# STM32C091 register map
File version: 1.1
CPU: CM0+ r0p0, little endian, MPU, no FPU, 4 interrupt priority bits
Registers are 32-bit, read-write, reset 0x0 unless marked. A register's access mark holds for its fields unless they carry their own. Offsets are from the block's base; [hi:lo] are bit positions; {n}, {i} and the like mark numbered series; 'fields as' and 'values as' point back to an identical list.

## TIM2 — TIM2 address block description
Base 0x40000000
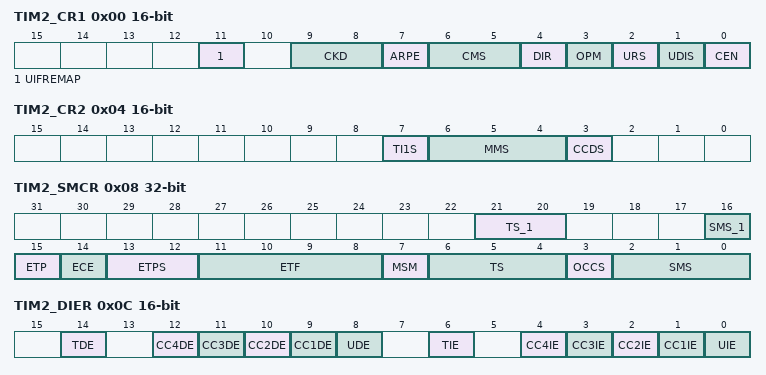
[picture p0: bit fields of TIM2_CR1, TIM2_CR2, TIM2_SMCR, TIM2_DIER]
0x00 TIM2_CR1 16-bit — TIM2 control register 1
  [11] UIFREMAP — UIF status bit remapping
    0=No remapping; 1=Remapping enabled
  [9:8] CKD — Clock division
    0=tless thansub>DTSless than/sub> = tless thansub>CK_INTless than/sub>; 1=tless thansub>DTSless than/sub> = 2 X tless thansub>CK_INTless than/sub>; 2=tless thansub>DTSless than/sub> = 4 X tless thansub>CK_INTless than/sub>
  [7] ARPE — Auto-reload preload enable
    0=TIMx_ARR register is not buffered; 1=TIMx_ARR register is buffered
  [6:5] CMS — Center-aligned mode selection
    0=Edge-aligned mode; 1=Center-aligned mode 1; 2=Center-aligned mode 2; 3=Center-aligned mode 3
  [4] DIR — Direction
    0=Counter used as upcounter; 1=Counter used as downcounter
  [3] OPM — One-pulse mode
    0=Counter is not stopped at update event; 1=Counter stops counting at the next update event (clearing the bit CEN)
  [2] URS — Update request source
    0=Any of the following events generate an update interrupt or DMA request if enabled; 1=Only counter overflow/underflow generates an update interrupt or DMA request if enabled
  [1] UDIS — Update disable
    0=UEV enabled; 1=UEV disabled
  [0] CEN — Counter enable
    0=Counter disabled; 1=Counter enabled
0x04 TIM2_CR2 16-bit — TIM2 control register 2
  [7] TI1S — TI1 selection
    0=The TIMx_CH1 pin is connected to TI1 input; 1=The TIMx_CH1, CH2 and CH3 pins are connected to the TI1 input (XOR combination) See also Section17
  [6:4] MMS — Master mode selection
    0=Reset - the UG bit from the TIMx_EGR register is used as trigger output (TRGO); 1=Enable - the Counter enable signal, CNT_EN, is used as trigger output (TRGO); 2=Update - The update event is selected as trigger output (TRGO); 3=Compare Pulse - The trigger output send a positive pulse when the CC1IF flag is to be set (even if it was already high), as soon as a capture or a compare match occurred; {v}=Compare - OC{v-3}REFC signal is used as trigger output (TRGO) (v=4..7)
  [3] CCDS — Capture/compare DMA selection
    0=CCx DMA request sent when CCx event occurs; 1=CCx DMA requests sent when update event occurs
0x08 TIM2_SMCR — TIM2 slave mode control register
  [21:20] TS_1 — TS[4:3]
  [16] SMS_1 — SMS[3]
  [15] ETP — External trigger polarity
    0=ETR is non-inverted, active at high level or rising edge; 1=ETR is inverted, active at low level or falling edge
  [14] ECE — External clock enable
    0=External clock mode 2 disabled; 1=External clock mode 2 enabled
  [13:12] ETPS — External trigger prescaler
    0=Prescaler OFF; 1=ETRP frequency divided by 2; 2=ETRP frequency divided by 4; 3=ETRP frequency divided by 8
  [11:8] ETF — External trigger filter
    0=No filter, sampling is done at fless thansub>DTSless than/sub>; 1=fless thansub>SAMPLINGless than/sub>=fless thansub>CK_INTless than/sub>, N=2; 2=fless thansub>SAMPLINGless than/sub>=fless thansub>CK_INTless than/sub>, N=4; 3=fless thansub>SAMPLINGless than/sub>=fless thansub>CK_INTless than/sub>, N=8; 4=fless thansub>SAMPLINGless than/sub>=fless thansub>DTSless than/sub>/2, N=6; 5=fless thansub>SAMPLINGless than/sub>=fless thansub>DTSless than/sub>/2, N=8; 6=fless thansub>SAMPLINGless than/sub>=fless thansub>DTSless than/sub>/4, N=6; 7=fless thansub>SAMPLINGless than/sub>=fless thansub>DTSless than/sub>/4, N=8; 8=fless thansub>SAMPLINGless than/sub>=fless thansub>DTSless than/sub>/8, N=6; 9=fless thansub>SAMPLINGless than/sub>=fless thansub>DTSless than/sub>/8, N=8; 10=fless thansub>SAMPLINGless than/sub>=fless thansub>DTSless than/sub>/16, N=5; 11=fless thansub>SAMPLINGless than/sub>=fless thansub>DTSless than/sub>/16, N=6; 12=fless thansub>SAMPLINGless than/sub>=fless thansub>DTSless than/sub>/16, N=8; 13=fless thansub>SAMPLINGless than/sub>=fless thansub>DTSless than/sub>/32, N=5; 14=fless thansub>SAMPLINGless than/sub>=fless thansub>DTSless than/sub>/32, N=6; 15=fless thansub>SAMPLINGless than/sub>=fless thansub>DTSless than/sub>/32, N=8
  [7] MSM — Master/Slave mode
    0=No action; 1=The effect of an event on the trigger input (TRGI) is delayed to allow a perfect synchronization between the current timer and its slaves (through TRGO)
  [6:4] TS — TS[2:0]: Trigger selection
    {v}=Internal Trigger {v} (ITR{v}) (v=0..3); 4=TI1 Edge Detector (TI1F_ED); 5=Filtered Timer Input 1 (TI1FP1); 6=Filtered Timer Input 2 (TI2FP2); 7=External Trigger input (ETRF)
  [3] OCCS — OCREF clear selection
    0=OCREF_CLR_INT is unconnected; 1=OCREF_CLR_INT is connected to ETRF
  [2:0] SMS — SMS[2:0]: Slave mode selection
    0=Slave mode disabled - if CEN = 1 then the prescaler is clocked directly by the internal clock; 1=Encoder mode 1 - Counter counts up/down on TI1FP1 edge depending on TI2FP2 level; 2=Encoder mode 2 - Counter counts up/down on TI2FP2 edge depending on TI1FP1 level; 3=Encoder mode 3 - Counter counts up/down on both TI1FP1 and TI2FP2 edges depending on the level of the other input; 4=Reset Mode - Rising edge of the selected trigger input (TRGI) reinitializes the counter and generates an update of the registers; 5=Gated Mode - The counter clock is enabled when the trigger input (TRGI) is high; 6=Trigger Mode - The counter starts at a rising edge of the trigger TRGI (but it is not reset); 7=External Clock Mode 1 - Rising edges of the selected trigger (TRGI) clock the counter
0x0C TIM2_DIER 16-bit — TIM2 DMA/Interrupt enable register
  [14] TDE — Trigger DMA request enable
    0=Trigger DMA request disabled; 1=Trigger DMA request enabled
  [n+8] CC{n}DE (n=1..4) — Capture/Compare {n} DMA request enable
    0=CC{n} DMA request disabled; 1=CC{n} DMA request enabled
  [8] UDE — Update DMA request enable
    0=Update DMA request disabled; 1=Update DMA request enabled
  [6] TIE — Trigger interrupt enable
    0=Trigger interrupt disabled; 1=Trigger interrupt enabled
  [n] CC{n}IE (n=1..4) — Capture/Compare {n} interrupt enable
    0=CC{n} interrupt disabled; 1=CC{n} interrupt enabled
  [0] UIE — Update interrupt enable
    0=Update interrupt disabled; 1=Update interrupt enabled
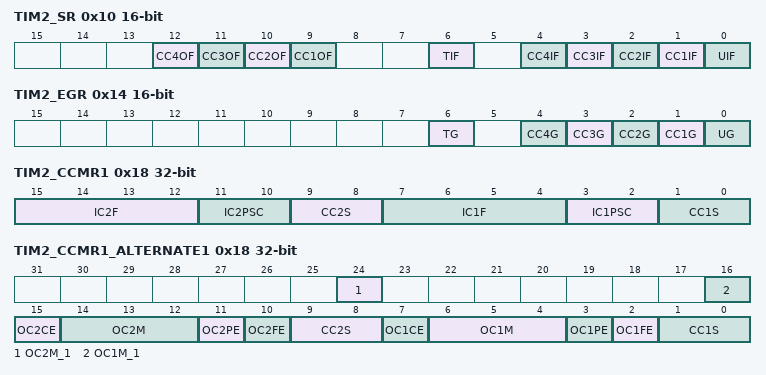
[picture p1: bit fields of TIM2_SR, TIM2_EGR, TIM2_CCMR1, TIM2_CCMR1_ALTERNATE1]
0x10 TIM2_SR 16-bit — TIM2 status register
  [12] CC4OF — Capture/Compare 4 overcapture flag
  [11] CC3OF — Capture/Compare 3 overcapture flag
  [10] CC2OF — Capture/compare 2 overcapture flag
  [9] CC1OF — Capture/Compare 1 overcapture flag
    0=No overcapture has been detected; 1=The counter value has been captured in TIMx_CCR1 register while CC1IF flag was already set
  [6] TIF — Trigger interrupt flag
    0=No trigger event occurred; 1=Trigger interrupt pending
  [4] CC4IF — Capture/Compare 4 interrupt flag
  [3] CC3IF — Capture/Compare 3 interrupt flag
  [2] CC2IF — Capture/Compare 2 interrupt flag
  [1] CC1IF — Capture/compare 1 interrupt flag
    0=No compare match / No input capture occurred; 1=A compare match or an input capture occurred
  [0] UIF — Update interrupt flag
    0=No update occurred; 1=Update interrupt pending
0x14 TIM2_EGR 16-bit wo — TIM2 event generation register
  [6] TG — Trigger generation
    0=No action; 1=The TIF flag is set in TIMx_SR register
  [4] CC4G — Capture/compare 4 generation
  [3] CC3G — Capture/compare 3 generation
  [2] CC2G — Capture/compare 2 generation
  [1] CC1G — Capture/compare 1 generation
    0=No action; 1=A capture/compare event is generated on channel 1:
  [0] UG — Update generation
    0=No action; 1=Re-initialize the counter and generates an update of the registers
0x18 TIM2_CCMR1 — TIM2 capture/compare mode register 1
  [15:12] IC2F — Input capture 2 filter
  [11:10] IC2PSC — Input capture 2 prescaler
  [9:8] CC2S — Capture/compare 2 selection
    0=CC2 channel is configured as output; 1=CC2 channel is configured as input, IC2 is mapped on TI2; 2=CC2 channel is configured as input, IC2 is mapped on TI1; 3=CC2 channel is configured as input, IC2 is mapped on TRC
  [7:4] IC1F — Input capture 1 filter
    0=No filter, sampling is done at f less thansub>DTSless than/sub>; 1=fless thansub>SAMPLINGless than/sub>=fless thansub>CK_INTless than/sub>, N=2; 2=fless thansub>SAMPLINGless than/sub>=fless thansub>CK_INTless than/sub>, N=4; 3=fless thansub>SAMPLINGless than/sub>=fless thansub>CK_INTless than/sub>, N=8; 4=fless thansub>SAMPLINGless than/sub>=fless thansub>DTSless than/sub>/2, N=6; 5=fless thansub>SAMPLINGless than/sub>=fless thansub>DTSless than/sub>/2, N=8; 6=fless thansub>SAMPLINGless than/sub>=fless thansub>DTSless than/sub>/4, N=6; 7=fless thansub>SAMPLINGless than/sub>=fless thansub>DTSless than/sub>/4, N=8; 8=fless thansub>SAMPLINGless than/sub>=fless thansub>DTSless than/sub>/8, N=6; 9=fless thansub>SAMPLINGless than/sub>=fless thansub>DTSless than/sub>/8, N=8; 10=fless thansub>SAMPLINGless than/sub>=fless thansub>DTSless than/sub>/16, N=5; 11=fless thansub>SAMPLINGless than/sub>=fless thansub>DTSless than/sub>/16, N=6; 12=fless thansub>SAMPLINGless than/sub>=fless thansub>DTSless than/sub>/16, N=8; 13=fless thansub>SAMPLINGless than/sub>=fless thansub>DTSless than/sub>/32, N=5; 14=fless thansub>SAMPLINGless than/sub>=fless thansub>DTSless than/sub>/32, N=6; 15=fless thansub>SAMPLINGless than/sub>=fless thansub>DTSless than/sub>/32, N=8
  [3:2] IC1PSC — Input capture 1 prescaler
    0=no prescaler, capture is done each time an edge is detected on the capture input; 1=capture is done once every 2 events; 2=capture is done once every 4 events; 3=capture is done once every 8 events
  [1:0] CC1S — Capture/Compare 1 selection
    0=CC1 channel is configured as output; 1=CC1 channel is configured as input, IC1 is mapped on TI1; 2=CC1 channel is configured as input, IC1 is mapped on TI2; 3=CC1 channel is configured as input, IC1 is mapped on TRC
0x18 TIM2_CCMR1_ALTERNATE1 (alternate view of TIM2_CCMR1) — TIM2 capture/compare mode register 1
  [24] OC2M_1 — OC2M[3]
  [16] OC1M_1 — OC1M[3]
  [15] OC2CE — Output compare 2 clear enable
  [14:12] OC2M — OC2M[2:0]: Output compare 2 mode
  [11] OC2PE — Output compare 2 preload enable
  [10] OC2FE — Output compare 2 fast enable
  [9:8] CC2S — Capture/Compare 2 selection
    values as TIM2_CCMR1.CC2S
  [7] OC1CE — Output compare 1 clear enable
    0=OC1Ref is not affected by the ETRF input; 1=OC1Ref is cleared as soon as a High level is detected on ETRF input
  [6:4] OC1M — OC1M[2:0]: Output compare 1 mode
    0=Frozen - The comparison between the output compare register TIMx_CCR1 and the counter TIMx_CNT has no effect on the outputs; 1=Set channel 1 to active level on match; 2=Set channel 1 to inactive level on match; 3=Toggle - OC1REF toggles when TIMx_CNT=TIMx_CCR1; 4=Force inactive level - OC1REF is forced low; 5=Force active level - OC1REF is forced high; 6=PWM mode 1 - In upcounting, channel 1 is active as long as TIMx_CNTless thanTIMx_CCR1 else inactive; 7=PWM mode 2 - In upcounting, channel 1 is inactive as long as TIMx_CNTless thanTIMx_CCR1 else active
  [3] OC1PE — Output compare 1 preload enable
    0=Preload register on TIMx_CCR1 disabled; 1=Preload register on TIMx_CCR1 enabled
  [2] OC1FE — Output compare 1 fast enable
    0=CC1 behaves normally depending on counter and CCR1 values even when the trigger is ON; 1=An active edge on the trigger input acts like a compare match on CC1 output
  [1:0] CC1S — Capture/Compare 1 selection
    values as TIM2_CCMR1.CC1S
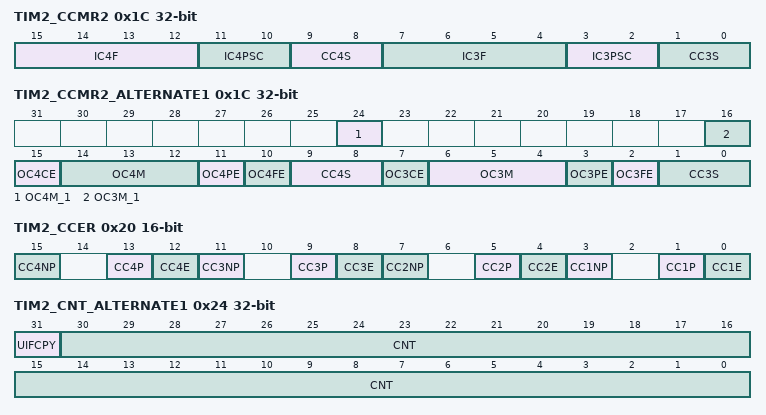
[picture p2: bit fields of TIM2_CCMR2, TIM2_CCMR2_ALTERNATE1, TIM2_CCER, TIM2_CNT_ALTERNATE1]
0x1C TIM2_CCMR2 — TIM2 capture/compare mode register 2
  [15:12] IC4F — Input capture 4 filter
  [11:10] IC4PSC — Input capture 4 prescaler
  [9:8] CC4S — Capture/Compare 4 selection
    0=CC4 channel is configured as output; 1=CC4 channel is configured as input, IC4 is mapped on TI4; 2=CC4 channel is configured as input, IC4 is mapped on TI3; 3=CC4 channel is configured as input, IC4 is mapped on TRC
  [7:4] IC3F — Input capture 3 filter
  [3:2] IC3PSC — Input capture 3 prescaler
  [1:0] CC3S — Capture/Compare 3 selection
    0=CC3 channel is configured as output; 1=CC3 channel is configured as input, IC3 is mapped on TI3; 2=CC3 channel is configured as input, IC3 is mapped on TI4; 3=CC3 channel is configured as input, IC3 is mapped on TRC
0x1C TIM2_CCMR2_ALTERNATE1 (alternate view of TIM2_CCMR2) — TIM2 capture/compare mode register 2
  [24] OC4M_1 — OC4M[3]
  [16] OC3M_1 — OC3M[3]
  [15] OC4CE — Output compare 4 clear enable
  [14:12] OC4M — OC4M[2:0]: Output compare 4 mode
  [11] OC4PE — Output compare 4 preload enable
  [10] OC4FE — Output compare 4 fast enable
  [9:8] CC4S — Capture/Compare 4 selection
    values as TIM2_CCMR2.CC4S
  [7] OC3CE — Output compare 3 clear enable
  [6:4] OC3M — OC3M[2:0]: Output compare 3 mode
  [3] OC3PE — Output compare 3 preload enable
  [2] OC3FE — Output compare 3 fast enable
  [1:0] CC3S — Capture/Compare 3 selection
    values as TIM2_CCMR2.CC3S
0x20 TIM2_CCER 16-bit — TIM2 capture/compare enable register
  [4n-1] CC{n}NP (n=1..4) — Capture/Compare {n} output Polarity.
  [13] CC4P — Capture/Compare 4 output Polarity.
  [12] CC4E — Capture/Compare 4 output enable.
  [9] CC3P — Capture/Compare 3 output Polarity.
  [8] CC3E — Capture/Compare 3 output enable.
  [5] CC2P — Capture/Compare 2 output Polarity.
  [4] CC2E — Capture/Compare 2 output enable.
  [1] CC1P — Capture/Compare 1 output Polarity.
    0=OC1 active high (output mode) / Edge sensitivity selection (input mode, see below); 1=OC1 active low (output mode) / Edge sensitivity selection (input mode, see below)
  [0] CC1E — Capture/Compare 1 output enable.
    0=Capture mode disabled / OC1 is not active; 1=Capture mode enabled / OC1 signal is output on the corresponding output pin
0x24 TIM2_CNT — TIM2 counter
  [31:0] CNT — Least significant part of counter value
0x24 TIM2_CNT_ALTERNATE1 (alternate view of TIM2_CNT) — TIM2 counter
  [31] UIFCPY — UIF Copy
  [30:0] CNT — Least significant part of counter value
0x28 TIM2_PSC 16-bit — TIM2 prescaler
  [15:0] PSC — Prescaler value
0x2C TIM2_ARR reset 0xFFFFFFFF — TIM2 auto-reload register
  [31:0] ARR — Low Auto-reload value
0x34 TIM2_CCR1 — TIM2 capture/compare register 1
  [31:0] CCR1 — Low Capture/Compare 1 value
0x38 TIM2_CCR2 — TIM2 capture/compare register 2
  [31:0] CCR2 — Low Capture/Compare 2 value
0x3C TIM2_CCR3 — TIM2 capture/compare register 3
  [31:0] CCR3 — Low Capture/Compare value
0x40 TIM2_CCR4 — TIM2 capture/compare register 4
  [31:0] CCR4 — Low Capture/Compare value
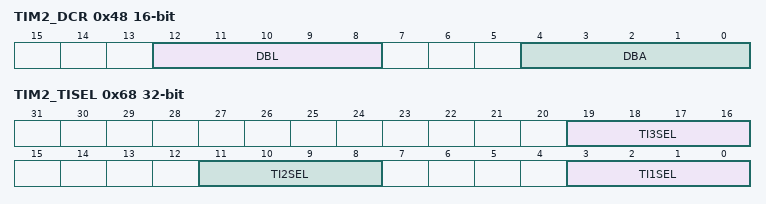
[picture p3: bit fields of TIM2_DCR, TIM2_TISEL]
0x48 TIM2_DCR 16-bit — TIM2 DMA control register
  [12:8] DBL — DMA burst length
    0=1 transfer,; 1=2 transfers,; 2=3 transfers,; 17=18 transfers
  [4:0] DBA — DMA base address
    0=TIMx_CR1; 1=TIMx_CR2; 2=TIMx_SMCR
0x4C TIM2_DMAR 16-bit — TIM2 DMA address for full transfer
  [15:0] DMAB — DMA register for burst accesses
0x60 TIM2_AF1 — TIM2 alternate function option register 1
  [17:14] ETRSEL — ETR source selection
    0=ETR legacy mode; 3=LSE; 4=MCO; 5=MCO2
0x68 TIM2_TISEL — TIM2 timer input selection register
  [19:16] TI3SEL — TI3[0] to TI3[15] input selection
    0=TIM2_CH3 input
  [11:8] TI2SEL — TI2[0] to TI2[15] input selection
    0=TIM2_CH2 input
  [3:0] TI1SEL — TI1[0] to TI1[15] input selection
    0=TIM2_CH1 input
